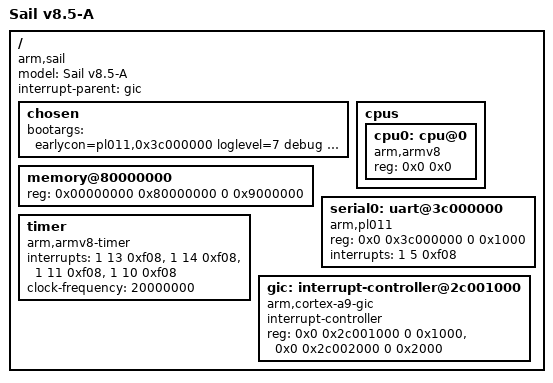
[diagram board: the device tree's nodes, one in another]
// SPDX-License-Identifier: GPL-2.0
/*
 * ARM Ltd.
 *
 * ARMv8 Foundation model DTS
 */

/dts-v1/;

/ {
	model = "Sail v8.5-A";
	compatible = "arm,sail";
	interrupt-parent = <&gic>;
	#address-cells = <2>;
	#size-cells = <2>;

	chosen {
	       bootargs = "earlycon=pl011,0x3c000000 loglevel=7 debug acpi=off sched_debug keep_bootcon nohlt";
	};

	cpus {
		#address-cells = <2>;
		#size-cells = <0>;

		cpu0: cpu@0 {
			device_type = "cpu";
			compatible = "arm,armv8";
			reg = <0x0 0x0>;
		};
	};

	memory@80000000 {
		device_type = "memory";
		reg = <0x00000000 0x80000000 0 0x9000000>;
	};

	serial0: uart@3c000000 {
		compatible = "arm,pl011", "arm,primecell";
		reg = <0x0 0x3c000000 0 0x1000>;
		interrupts = <1 5 0xf08>;
	};

	timer {
		compatible = "arm,armv8-timer";
		interrupts = <1 13 0xf08>,
			     <1 14 0xf08>,
			     <1 11 0xf08>,
			     <1 10 0xf08>;
		clock-frequency = <20000000>;
	};

	gic: interrupt-controller@2c001000 {
		compatible = "arm,cortex-a9-gic";
		#interrupt-cells = <3>;
		#address-cells = <2>;
		interrupt-controller;
		reg = <0x0 0x2c001000 0 0x1000>,
		      <0x0 0x2c002000 0 0x2000>;
	};

};
